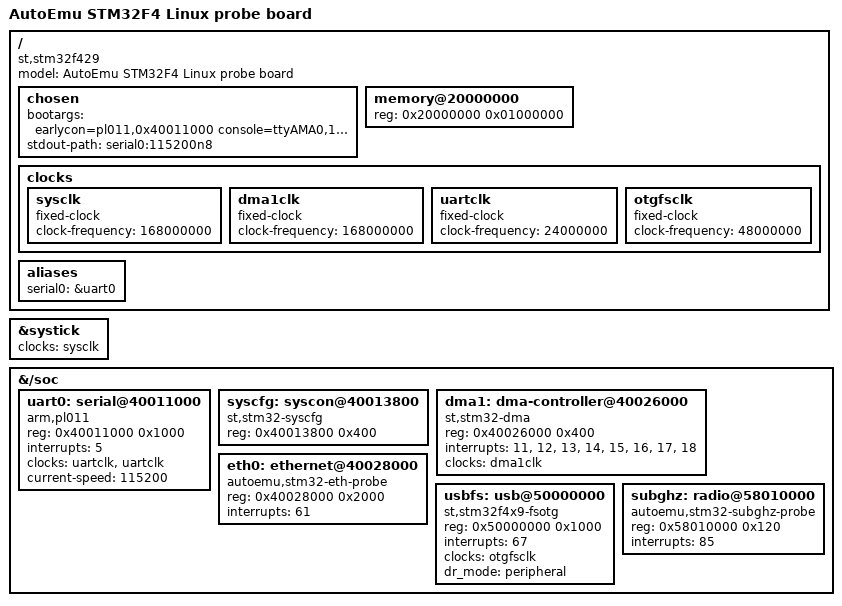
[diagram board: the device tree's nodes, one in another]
/dts-v1/;

#include "armv7-m.dtsi"

/ {
	model = "AutoEmu STM32F4 Linux probe board";
	compatible = "st,stm32f429";
	#address-cells = <1>;
	#size-cells = <1>;

	chosen {
		bootargs = "earlycon=pl011,0x40011000 console=ttyAMA0,115200 ignore_loglevel loglevel=8 initcall_debug panic=-1 lpj=1680000";
		stdout-path = "serial0:115200n8";
	};

	memory@20000000 {
		device_type = "memory";
		reg = <0x20000000 0x01000000>;
	};

	clocks {
		sysclk: sysclk {
			compatible = "fixed-clock";
			#clock-cells = <0>;
			clock-frequency = <168000000>;
		};

		dma1clk: dma1clk {
			compatible = "fixed-clock";
			#clock-cells = <0>;
			clock-frequency = <168000000>;
		};

		uartclk: uartclk {
			compatible = "fixed-clock";
			#clock-cells = <0>;
			clock-frequency = <24000000>;
		};

		otgfsclk: otgfsclk {
			compatible = "fixed-clock";
			#clock-cells = <0>;
			clock-frequency = <48000000>;
		};
	};

	aliases {
		serial0 = &uart0;
	};
};

&systick {
	clocks = <&sysclk>;
	status = "okay";
};

&{/soc} {
	uart0: serial@40011000 {
		compatible = "arm,pl011", "arm,primecell";
		reg = <0x40011000 0x1000>;
		interrupts = <5>;
		clocks = <&uartclk>, <&uartclk>;
		clock-names = "uartclk", "apb_pclk";
		current-speed = <115200>;
		status = "okay";
	};

	syscfg: syscon@40013800 {
		compatible = "st,stm32-syscfg", "syscon";
		reg = <0x40013800 0x400>;
	};

	dma1: dma-controller@40026000 {
		compatible = "st,stm32-dma";
		reg = <0x40026000 0x400>;
		interrupts = <11>,
			     <12>,
			     <13>,
			     <14>,
			     <15>,
			     <16>,
			     <17>,
			     <18>;
		clocks = <&dma1clk>;
		#dma-cells = <4>;
		status = "okay";
	};

	eth0: ethernet@40028000 {
		compatible = "autoemu,stm32-eth-probe";
		reg = <0x40028000 0x2000>;
		interrupts = <61>;
		status = "okay";
	};

	usbfs: usb@50000000 {
		compatible = "st,stm32f4x9-fsotg";
		reg = <0x50000000 0x1000>;
		interrupts = <67>;
		clocks = <&otgfsclk>;
		clock-names = "otg";
		dr_mode = "peripheral";
		status = "okay";
	};

	subghz: radio@58010000 {
		compatible = "autoemu,stm32-subghz-probe";
		reg = <0x58010000 0x120>;
		interrupts = <85>;
		status = "okay";
	};
};
